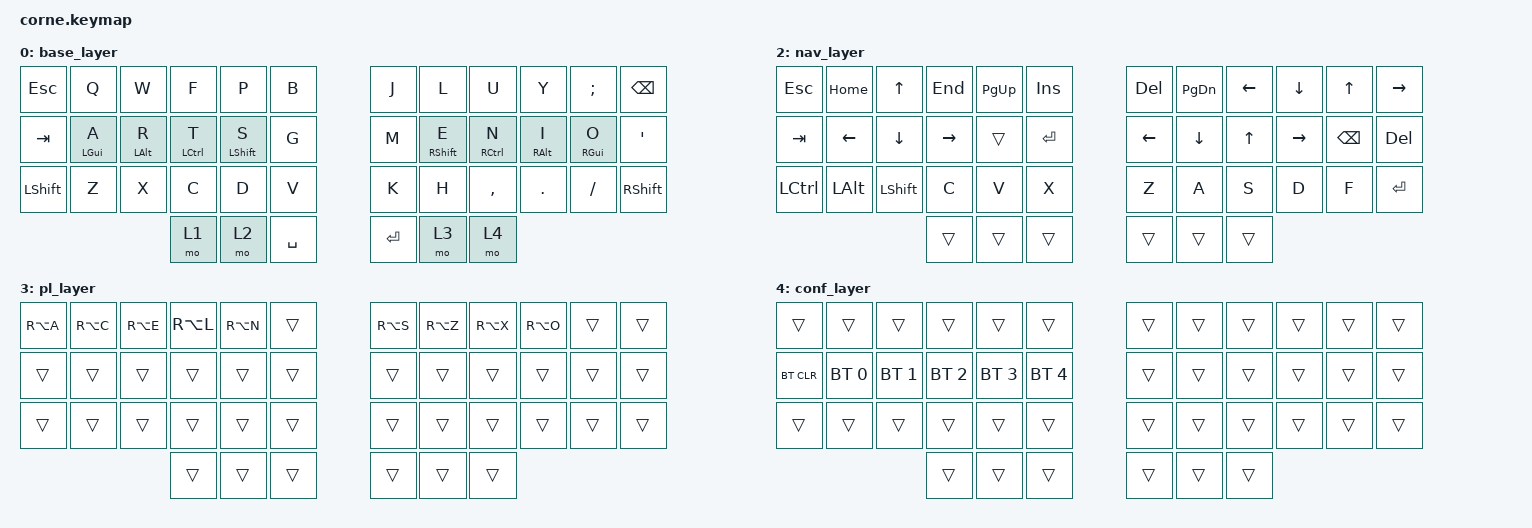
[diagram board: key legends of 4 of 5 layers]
#include <behaviors.dtsi>
#include <dt-bindings/zmk/keys.h>
#include <dt-bindings/zmk/bt.h>

/ {
    keymap {
        compatible = "zmk,keymap";

// =========================
// BASE (Colemak-DH + HRM)
// =========================
// |  ESC   |  Q        |  W        |  F        |  P        |  B        |       |  J        |  L        |  U        |  Y        |  ;      |  BSPC  |
// |  TAB   |  A(LGUI)  |  R(LALT)  |  T(LCTL)  |  S(LSHFT) |  G        |       |  M        |  E(RSHFT) |  N(RCTL)  |  I(RALT)  | O(RGUI) |  '     |
// | LSHIFT |  Z        |  X        |  C        |  D        |  V        |       |  K        |  H        |  ,        |  .        |  /      | RSHIFT |
//                                                 | SYM | NAV |  ENTER |       |  ENTER | PL | CONF |
        base_layer {
            bindings = <
   &kp ESC      &kp Q        &kp W       &kp F       &kp P          &kp B          &kp J   &kp L       &kp U       &kp Y   &kp SEMI        &kp BSPC
   &kp TAB      &hm LGUI A   &hm LALT R  &hm LCTL T  &hm LSHFT S    &kp G          &kp M   &hm RSHFT E &hm RCTL N  &hm RALT I  &hm RGUI O  &kp SQT
   &kp LSHFT    &kp Z        &kp X       &kp C       &kp D          &kp V          &kp K   &kp H       &kp COMMA   &kp DOT     &kp FSLH    &kp RSHIFT
                                                     &mo 1 &mo 2 &kp SPACE         &kp ENTER &mo 3 &mo 4
            >;
        };

        symbol_layer {
         // =========================
         // [1] SYMBOLS (symbol_layer)
         // =========================
         // |  !        |  @        |  #        |  $        |  %        |  ^      |       |  &        |  *        |  (        |  )        |  -     |  =    |
         // |  ~        |  |        |  {        |  }        |  [        |  ]      |       |  _        |  +        |  <        |  >        |  :     |  ;    |
         // |  `        |  \        |  /        |  ?        |  .        |  ,      |       |  ,        |  .        |  /        |  ?        |  |     |  `    |
         //                         | TRAN | TRAN | TRAN |       | TRAN | TRAN |
                 bindings = <
         &kp EXCL &kp AT &kp HASH &kp DLLR &kp PRCNT   &kp CARET &kp AMPS  &kp ASTRK &kp LPAR &kp RPAR &kp MINUS &kp EQUAL
         &kp TILDE   &kp PIPE &kp LBRC  &kp RBRC &kp G   &kp LBKT  &kp LBKT   &kp UNDER &kp PLUS &kp LT  &kp GT &kp COLON &kp SEMI
         &kp GRAVE   &kp BSLH       &kp FSLH       &kp QMARK       &kp DOT   &kp COMMA       &kp COMMA   &kp DOT     &kp FSLH   &kp QMARK     &kp PIPE    &kp GRAVE
                                                       &trans &trans &trans      &trans &trans &trans
                                 >;
                         };

        nav_layer {
          // =========================
          // [2] NAVIGATION (nav_layer)
          // =========================
          // |  ESC      | HOME      | UP        | END       | PG_UP     | INS     |       | DEL       | PG_DN     | LEFT      | DOWN      | UP     | RIGHT |
          // |  TAB      | LEFT      | DOWN      | UP        | RIGHT     | ENTER   |       | LEFT      | DOWN      | UP        | RIGHT     | BSPC   | DEL   |
          // |  LCTRL    | LALT      | LSHIFT    | C         | V         | X       |       | Z         | A         | S         | D         | F      | ENTER |
          //                         | TRAN | TRAN | TRAN |       | TRAN | TRAN |
                                  bindings = <
          &kp  ESC  &kp HOME &kp UP &kp END &kp PG_UP &kp INS   &kp DEL &kp PG_DN  &kp LEFT &kp DOWN &kp UP &kp RIGHT
          &kp TAB &kp LEFT   &kp DOWN &kp RIGHT   &trans   &kp RET      &kp LEFT &kp DOWN &kp UP  &kp RIGHT &kp BSPC &kp DEL
          &kp LCTRL &kp LALT   &kp LSHIFT &kp C   &kp V   &kp X      &kp Z &kp A  &kp S  &kp D &kp F &kp RET
                                       &trans &trans    &trans    &trans   &trans     &trans
                                  >;
        };

        pl_layer {
// =========================
// [3] POLISH (pl_layer)
// =========================
// |  Ą        |  Ć        |  Ę        |  Ł        |  Ń        | TRANS   |       |  Ś        |  Ź        |  Ż        |  Ó        | TRANS  | TRANS |
// |  TRANS    | TRANS     | TRANS     | TRANS     | TRANS     | TRANS   |       | TRANS     | TRANS     | TRANS     | TRANS     | TRANS  | TRANS |
// |  TRANS    | TRANS     | TRANS     | TRANS     | TRANS     | TRANS   |       | TRANS     | TRANS     | TRANS     | TRANS     | TRANS  | TRANS |
//                         | TRAN | TRAN | TRAN |       | TRAN | TRAN |
                                        bindings = <
    &kp RA(A) &kp RA(C) &kp RA(E) &kp RA(L) &kp RA(N) &trans     &kp RA(S) &kp RA(Z) &kp RA(X) &kp RA(O) &trans &trans
    &trans &trans &trans &trans &trans &trans     &trans &trans &trans &trans &trans &trans
    &trans &trans &trans &trans &trans &trans     &trans &trans &trans &trans &trans &trans
                      &trans &trans    &trans    &trans   &trans     &trans
            >;
        };

        conf_layer {
        // =========================
        // [4] CONF (conf_layer)
        // =========================
        // |  Ą        |  Ć        |  Ę        |  Ł        |  Ń        | TRANS   |       |  Ś        |  Ź        |  Ż        |  Ó        | TRANS  | TRANS |
        // |  TRANS    | TRANS     | TRANS     | TRANS     | TRANS     | TRANS   |       | TRANS     | TRANS     | TRANS     | TRANS     | TRANS  | TRANS |
        // |  TRANS    | TRANS     | TRANS     | TRANS     | TRANS     | TRANS   |       | TRANS     | TRANS     | TRANS     | TRANS     | TRANS  | TRANS |
        //                         | TRAN | TRAN | TRAN |       | TRAN | TRAN |
                                                bindings = <
   &trans &trans &trans &trans &trans &trans     &trans &trans &trans &trans &trans &trans
   &bt BT_CLR &bt BT_SEL 0 &bt BT_SEL 1 &bt BT_SEL 2 &bt BT_SEL 3 &bt BT_SEL 4     &trans &trans &trans &trans &trans &trans
   &trans &trans &trans &trans &trans &trans     &trans &trans &trans &trans &trans &trans
                              &trans &trans    &trans    &trans   &trans     &trans
                    >;
                };
    };

    // =========================
    // HOME ROW MODS (STABLE)
    // =========================
    behaviors {
        hm: homerow_mod {
            compatible = "zmk,behavior-hold-tap";
            label = "HM";
            #binding-cells = <2>;
            tapping-term-ms = <450>;
            quick-tap-ms = <200>;
            flavor = "tap-preferred";
            bindings = <&kp>, <&kp>;
        };
    };
};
